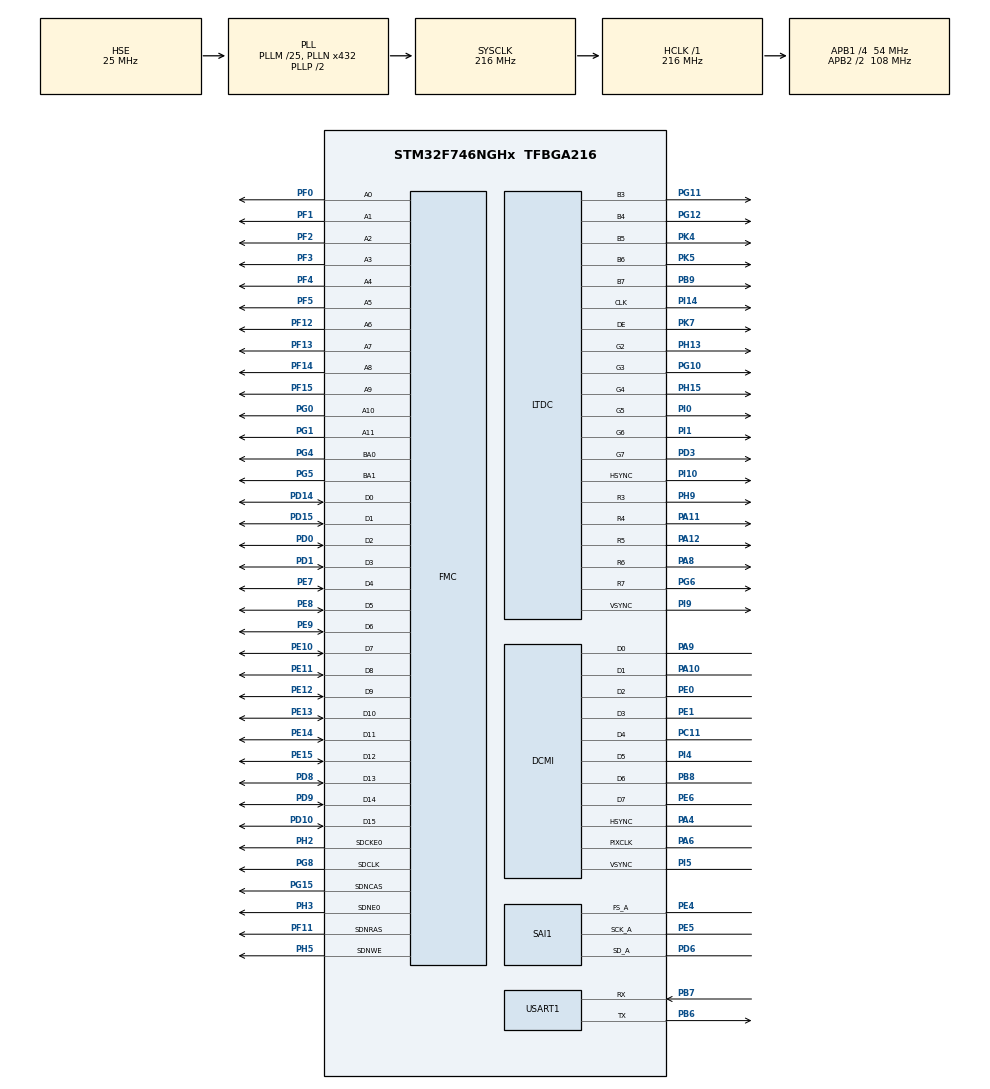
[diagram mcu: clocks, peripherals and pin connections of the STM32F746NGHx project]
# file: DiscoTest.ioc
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SH.FMC_D7_DA7.0=FMC_D7,sd-16b-d1
PK5.Signal=LTDC_B6
FMC.RCDDelay1=2
SH.FMC_A0.0=FMC_A0,12b-sda1
PG8.Signal=FMC_SDCLK
PG4.Signal=FMC_A14_BA0
PG0.Signal=FMC_A10
FMC.LoadToActiveDelay1=2
SH.FMC_D5_DA5.0=FMC_D5,sd-16b-d1
PG6.Mode=RGB565
SAI1.Instance-SAI_A_Master=SAI$Index_Block_A
RCC.SYSCLKSource=RCC_SYSCLKSOURCE_PLLCLK
SH.FMC_A15_BA1.0=FMC_BA1,FourSdramBanks1
SH.FMC_D9_DA9.0=FMC_D9,sd-16b-d1
PH5.Signal=FMC_SDNWE
PA4.Mode=Slave_8_bits_External_Synchro
SH.FMC_SDNWE.0=FMC_SDNWE,12b-sda1
PH9.Signal=LTDC_R3
SH.FMC_D11_DA11.0=FMC_D11,sd-16b-d1
RCC.APB2TimFreq_Value=216000000
PB6.Signal=USART1_TX
PH1/OSC_OUT.Signal=RCC_OSC_OUT
PB6.Mode=Asynchronous
PD0.Signal=FMC_D2_DA2
PD8.Signal=FMC_D13_DA13
PE5.Signal=SAI1_SCK_A
PE1.Signal=DCMI_D3
FMC.SelfRefreshTime1=4
LTDC.PixelFormat_L0=LTDC_PIXEL_FORMAT_RGB565
PK7.Mode=RGB565
PE9.Signal=FMC_D6_DA6
SH.FMC_A2.0=FMC_A2,12b-sda1
PA8.Signal=LTDC_R6
SH.FMC_D1_DA1.0=FMC_D1,sd-16b-d1
PF3.Signal=FMC_A3
PD3.Mode=RGB565
PE10.Signal=FMC_D7_DA7
LTDC.HSync=41
PB9.Signal=LTDC_B7
Mcu.Package=TFBGA216
NVIC.TimeBase=TIM1_UP_TIM10_IRQn
NVIC.TimeBaseIP=TIM1
PA10.Signal=DCMI_D1
FMC.WriteRecoveryTime1=2
PC11.Mode=Slave_8_bits_External_Synchro
SAI1.VirtualMode-SAI_A_Master=VM_MASTER
SH.FMC_A1.0=FMC_A1,12b-sda1
PH2.Signal=FMC_SDCKE0
RCC.APB2CLKDivider=RCC_HCLK_DIV2
SH.FMC_SDCLK.0=FMC_SDCLK,12b-sda1
LTDC.VSync=10
PF14.Signal=FMC_A8
RCC.APB1TimFreq_Value=108000000
VP_DMA2D_VS_DMA2D.Mode=DMA2D_Activate
FMC.RowCycleDelay2=6
FMC.RowCycleDelay1=6
SH.FMC_D3_DA3.0=FMC_D3,sd-16b-d1
PD15.Signal=FMC_D1_DA1
PG12.Signal=LTDC_B4
PK4.Signal=LTDC_B5
SH.FMC_A4.0=FMC_A4,12b-sda1
PH15.Signal=LTDC_G4
FREERTOS.Tasks01=defaultTask,24,1280,StartDefaultTask,Default,NULL,Dynamic,NULL,NULL;myTask02,8,128,StartTask02,Default,NULL,Dynamic,NULL,NULL;myTask03,8,128,StartTask03,Default,NULL,Dynamic,NULL,NULL;myTask04,8,128,StartTask04,Default,NULL,Dynamic,NULL,NULL;myTask05,8,128,StartTask05,Default,NULL,Dynamic,NULL,NULL
PH13.Signal=LTDC_G2
PI4.Mode=Slave_8_bits_External_Synchro
PG5.Signal=FMC_A15_BA1
SH.FMC_D10_DA10.0=FMC_D10,sd-16b-d1
PD3.Signal=LTDC_G7
PE1.Mode=Slave_8_bits_External_Synchro
PI10.Mode=RGB565
PD1.Signal=FMC_D3_DA3
RCC.APB1CLKDivider=RCC_HCLK_DIV4
PD6.Mode=SAI_A_Master
SAI1.RealAudioFreq-SAI_A_Master=187.5 KHz
PG10.Signal=LTDC_G3
PD10.Signal=FMC_D15_DA15
SH.FMC_A3.0=FMC_A3,12b-sda1
FMC.CASLatency1=FMC_SDRAM_CAS_LATENCY_2
SH.FMC_D15_DA15.0=FMC_D15,sd-16b-d1
PH9.Mode=RGB565
PA9.Signal=DCMI_D0
SH.FMC_A6.0=FMC_A6,12b-sda1
PE14.Signal=FMC_D11_DA11
PE6.Mode=Slave_8_bits_External_Synchro
PE15.Signal=FMC_D12_DA12
PE8.Signal=FMC_D5_DA5
PI1.Signal=LTDC_G6
PF13.Signal=FMC_A7
SH.FMC_SDNCAS.0=FMC_SDNCAS,12b-sda1
PA13.Mode=Serial_Wire
PA4.Signal=DCMI_HSYNC
PK4.Mode=RGB565
PG11.Mode=RGB565
SH.FMC_A5.0=FMC_A5,12b-sda1
PA11.Signal=LTDC_R4
ProjectManager.HeapSize=0x2000
NVIC.TIM1_UP_TIM10_IRQn=true\:0\:0\:false\:false\:true\:false\:false\:true
NVIC.PriorityGroup=NVIC_PRIORITYGROUP_4
PB8.Mode=Slave_8_bits_External_Synchro
PA8.Mode=RGB565
PF4.Signal=FMC_A4
Mcu.Family=STM32F7
PK7.Signal=LTDC_DE
PA6.Mode=Slave_8_bits_External_Synchro
SH.FMC_A8.0=FMC_A8,12b-sda1
RCC.CortexFreq_Value=216000000
PG6.Signal=LTDC_R7
SH.FMC_D14_DA14.0=FMC_D14,sd-16b-d1
LTDC.HBP=73
SH.FMC_D6_DA6.0=FMC_D6,sd-16b-d1
PA11.Mode=RGB565
SH.FMC_A14_BA0.0=FMC_BA0,FourSdramBanks1
SH.FMC_A11.0=FMC_A11,12b-sda1
PI5.Mode=Slave_8_bits_External_Synchro
PG11.Signal=LTDC_B3
PG15.Signal=FMC_SDNCAS
ProjectManager.StackSize=0x4000
VP_FREERTOS_VS_CMSIS_V2.Mode=CMSIS_V2
PH3.Mode=SdramChipSelect1_1
SH.FMC_A7.0=FMC_A7,12b-sda1
PA12.Signal=LTDC_R5
PH0/OSC_IN.Mode=HSE-External-Oscillator
RCC.HCLKFreq_Value=216000000
LTDC.WindowX1_L0=480
PF12.Signal=FMC_A6
PI9.Mode=RGB565
SH.FMC_A10.0=FMC_A10,12b-sda1
RCC.AHBFreq_Value=216000000
RCC.HSE_VALUE=25000000
SH.FMC_D8_DA8.0=FMC_D8,sd-16b-d1
FMC.ExitSelfRefreshDelay1=6
FMC.RPDelay2=2
FMC.RPDelay1=2
PI14.Mode=RGB565
SH.FMC_D2_DA2.0=FMC_D2,sd-16b-d1
PE13.Signal=FMC_D10_DA10
PA14.Mode=Serial_Wire
PI5.Signal=DCMI_VSYNC
VP_SYS_VS_tim1.Mode=TIM1
PI0.Signal=LTDC_G5
PF11.Signal=FMC_SDNRAS
LTDC.HFP=32
PB7.Signal=USART1_RX
PE4.Mode=SAI_A_Master
SH.FMC_SDNRAS.0=FMC_SDNRAS,12b-sda1
LTDC.ActiveW=480
PH1/OSC_OUT.Mode=HSE-External-Oscillator
PE4.Signal=SAI1_FS_A
PA6.Signal=DCMI_PIXCLK
SH.FMC_D0_DA0.0=FMC_D0,sd-16b-d1
SH.FMC_A9.0=FMC_A9,12b-sda1
SH.FMC_D4_DA4.0=FMC_D4,sd-16b-d1
PI1.Mode=RGB565
PF5.Signal=FMC_A5
PF0.Signal=FMC_A0
PH2.Mode=SdramChipSelect1_1
PE7.Signal=FMC_D4_DA4
PD6.Signal=SAI1_SD_A
RCC.PLLSourceVirtual=RCC_PLLSOURCE_HSE
CORTEX_M7.CPU_ICache=Enabled
LTDC.WindowY1_L0=272
PA10.Mode=Slave_8_bits_External_Synchro
PG1.Signal=FMC_A11
PC11.Signal=DCMI_D4
PI14.Signal=LTDC_CLK
PG10.Mode=RGB565
PI10.Signal=LTDC_HSYNC
PD9.Signal=FMC_D14_DA14
SAI1.MClockEnable-SAI_A_Master=SAI_MASTERCLOCK_DISABLE
USART1.VirtualMode-Asynchronous=VM_ASYNC
PA13.Signal=SYS_JTMS-SWDIO
PA9.Mode=Slave_8_bits_External_Synchro
ProjectManager.TargetToolchain=STM32CubeIDE
SH.FMC_D13_DA13.0=FMC_D13,sd-16b-d1
LTDC.ActiveH=272
SAI1.ErrorAudioFreq-SAI_A_Master=-2.34 %
PB9.Mode=RGB565
PI0.Mode=RGB565
PF2.Signal=FMC_A2
RCC.USBFreq_Value=216000000
PH13.Mode=RGB565
PE11.Signal=FMC_D8_DA8
RCC.LSE_VALUE=32768
PK5.Mode=RGB565
board=custom
PG12.Mode=RGB565
RCC.VCOOutputFreq_Value=432000000
PI9.Signal=LTDC_VSYNC
PH0/OSC_IN.Signal=RCC_OSC_IN
RCC.APB2Freq_Value=108000000
LTDC.Layers=0
PI4.Signal=DCMI_D5
PE5.Mode=SAI_A_Master
SH.FMC_D12_DA12.0=FMC_D12,sd-16b-d1
PF15.Signal=FMC_A9
PF1.Signal=FMC_A1
PE6.Signal=DCMI_D7
Mcu.Name=STM32F746NGHx
PE0.Signal=DCMI_D2
PE12.Signal=FMC_D9_DA9
PH15.Mode=RGB565
PD14.Signal=FMC_D0_DA0
LTDC.WindowY0_L0=0
RCC.SYSCLKFreq_VALUE=216000000
PA12.Mode=RGB565
LTDC.WindowX0_L0=0
PB7.Mode=Asynchronous
PA14.Signal=SYS_JTCK-SWCLK
RCC.HSI_VALUE=16000000
PH3.Signal=FMC_SDNE0
RCC.PLLM=25
RCC.PLLN=432
PB8.Signal=DCMI_D6
CORTEX_M7.CPU_DCache=Enabled
RCC.APB1Freq_Value=54000000
PE0.Mode=Slave_8_bits_External_Synchro

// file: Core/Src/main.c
/* USER CODE BEGIN Header */
/**
  ******************************************************************************
  * @file           : main.c
  * @brief          : Main program body
  ******************************************************************************
  * @attention
  *
  * <h2><center>&copy; Copyright (c) 2021 STMicroelectronics.
  * All rights reserved.</center></h2>
  *
  * This software component is licensed by ST under Ultimate Liberty license
  * SLA0044, the "License"; You may not use this file except in compliance with
  * the License. You may obtain a copy of the License at:
  *                             www.st.com/SLA0044
  *
  ******************************************************************************
  */
/* USER CODE END Header */
#include "main.h"
#include "cmsis_os.h"

/* USER CODE BEGIN Includes */

#include "stdlib.h"
#include "stm32746g_discovery.h"
#include "stm32746g_discovery_lcd.h"
#include "stm32746g_discovery_camera.h"

/* USER CODE END Includes */

DCMI_HandleTypeDef hdcmi;

DMA2D_HandleTypeDef hdma2d;

LTDC_HandleTypeDef hltdc;

SAI_HandleTypeDef hsai_BlockA1;

UART_HandleTypeDef huart1;

SDRAM_HandleTypeDef hsdram1;

/* Definitions for defaultTask */
osThreadId_t defaultTaskHandle;
const osThreadAttr_t defaultTask_attributes = {
  .name = "defaultTask",
  .stack_size = 1280 * 4,
  .priority = (osPriority_t) osPriorityNormal,
};
/* Definitions for myTask02 */
osThreadId_t myTask02Handle;
const osThreadAttr_t myTask02_attributes = {
  .name = "myTask02",
  .stack_size = 128 * 4,
  .priority = (osPriority_t) osPriorityLow,
};
/* Definitions for myTask03 */
osThreadId_t myTask03Handle;
const osThreadAttr_t myTask03_attributes = {
  .name = "myTask03",
  .stack_size = 128 * 4,
  .priority = (osPriority_t) osPriorityLow,
};
/* Definitions for myTask04 */
osThreadId_t myTask04Handle;
const osThreadAttr_t myTask04_attributes = {
  .name = "myTask04",
  .stack_size = 128 * 4,
  .priority = (osPriority_t) osPriorityLow,
};
/* Definitions for myTask05 */
osThreadId_t myTask05Handle;
const osThreadAttr_t myTask05_attributes = {
  .name = "myTask05",
  .stack_size = 128 * 4,
  .priority = (osPriority_t) osPriorityLow,
};
/* USER CODE BEGIN PV */

#ifndef USE_FULL_ASSERT
uint32_t    ErrorCounter = 0;
#endif

/* USER CODE END PV */

void SystemClock_Config(void);
static void MX_GPIO_Init(void);
static void MX_USART1_UART_Init(void);
static void MX_DMA2D_Init(void);
static void MX_FMC_Init(void);
static void MX_LTDC_Init(void);
static void MX_DCMI_Init(void);
static void MX_SAI1_Init(void);
void StartDefaultTask(void *argument);
void StartTask02(void *argument);
void StartTask03(void *argument);
void StartTask04(void *argument);
void StartTask05(void *argument);

/* USER CODE BEGIN 0 */
#define LCD_FRAME_BUFFER	SDRAM_DEVICE_ADDR
/* USER CODE END 0 */

int main(void)
{

  /* Enable I-Cache---------------------------------------------------------*/
  SCB_EnableICache();

  /* Enable D-Cache---------------------------------------------------------*/
  SCB_EnableDCache();

  /* MCU Configuration--------------------------------------------------------*/

  /* Reset of all peripherals, Initializes the Flash interface and the Systick. */
  HAL_Init();

  /* Configure the system clock */
  SystemClock_Config();

  /* Initialize all configured peripherals */
  MX_GPIO_Init();
  MX_USART1_UART_Init();
  MX_DMA2D_Init();
  MX_FMC_Init();
  MX_LTDC_Init();
  MX_DCMI_Init();
  MX_SAI1_Init();
  /* USER CODE BEGIN 2 */

  BSP_LCD_Init();
  BSP_LCD_LayerDefaultInit(LTDC_ACTIVE_LAYER, LCD_FRAME_BUFFER);
  BSP_LCD_SelectLayer(LTDC_ACTIVE_LAYER);
  BSP_LCD_DisplayOn();
  BSP_LCD_Clear(LCD_COLOR_BLACK);

  BSP_CAMERA_Init();
  /* USER CODE END 2 */

  /* Init scheduler */
  osKernelInitialize();

  /* Create the thread(s) */
  /* creation of defaultTask */
  defaultTaskHandle = osThreadNew(StartDefaultTask, NULL, &defaultTask_attributes);

  /* creation of myTask02 */
  myTask02Handle = osThreadNew(StartTask02, NULL, &myTask02_attributes);

  /* creation of myTask03 */
  myTask03Handle = osThreadNew(StartTask03, NULL, &myTask03_attributes);

  /* creation of myTask04 */
  myTask04Handle = osThreadNew(StartTask04, NULL, &myTask04_attributes);

  /* creation of myTask05 */
  myTask05Handle = osThreadNew(StartTask05, NULL, &myTask05_attributes);

  /* Start scheduler */
  osKernelStart();

  /* We should never get here as control is now taken by the scheduler */
  /* Infinite loop */
  while (1)
  {

  }
}

void SystemClock_Config(void)
{
  RCC_OscInitTypeDef RCC_OscInitStruct = {0};
  RCC_ClkInitTypeDef RCC_ClkInitStruct = {0};
  RCC_PeriphCLKInitTypeDef PeriphClkInitStruct = {0};

  /** Configure the main internal regulator output voltage
  */
  __HAL_RCC_PWR_CLK_ENABLE();
  __HAL_PWR_VOLTAGESCALING_CONFIG(PWR_REGULATOR_VOLTAGE_SCALE1);
  /** Initializes the RCC Oscillators according to the specified parameters
  * in the RCC_OscInitTypeDef structure.
  */
  RCC_OscInitStruct.OscillatorType = RCC_OSCILLATORTYPE_HSE;
  RCC_OscInitStruct.HSEState = RCC_HSE_ON;
  RCC_OscInitStruct.PLL.PLLState = RCC_PLL_ON;
  RCC_OscInitStruct.PLL.PLLSource = RCC_PLLSOURCE_HSE;
  RCC_OscInitStruct.PLL.PLLM = 25;
  RCC_OscInitStruct.PLL.PLLN = 432;
  RCC_OscInitStruct.PLL.PLLP = RCC_PLLP_DIV2;
  RCC_OscInitStruct.PLL.PLLQ = 2;
  if (HAL_RCC_OscConfig(&RCC_OscInitStruct) != HAL_OK)
  {
    Error_Handler();
  }
  /** Activate the Over-Drive mode
  */
  if (HAL_PWREx_EnableOverDrive() != HAL_OK)
  {
    Error_Handler();
  }
  /** Initializes the CPU, AHB and APB buses clocks
  */
  RCC_ClkInitStruct.ClockType = RCC_CLOCKTYPE_HCLK|RCC_CLOCKTYPE_SYSCLK
                              |RCC_CLOCKTYPE_PCLK1|RCC_CLOCKTYPE_PCLK2;
  RCC_ClkInitStruct.SYSCLKSource = RCC_SYSCLKSOURCE_PLLCLK;
  RCC_ClkInitStruct.AHBCLKDivider = RCC_SYSCLK_DIV1;
  RCC_ClkInitStruct.APB1CLKDivider = RCC_HCLK_DIV4;
  RCC_ClkInitStruct.APB2CLKDivider = RCC_HCLK_DIV2;

  if (HAL_RCC_ClockConfig(&RCC_ClkInitStruct, FLASH_LATENCY_7) != HAL_OK)
  {
    Error_Handler();
  }
  PeriphClkInitStruct.PeriphClockSelection = RCC_PERIPHCLK_LTDC|RCC_PERIPHCLK_USART1
                              |RCC_PERIPHCLK_SAI1;
  PeriphClkInitStruct.PLLSAI.PLLSAIN = 192;
  PeriphClkInitStruct.PLLSAI.PLLSAIR = 2;
  PeriphClkInitStruct.PLLSAI.PLLSAIQ = 2;
  PeriphClkInitStruct.PLLSAI.PLLSAIP = RCC_PLLSAIP_DIV2;
  PeriphClkInitStruct.PLLSAIDivQ = 1;
  PeriphClkInitStruct.PLLSAIDivR = RCC_PLLSAIDIVR_2;
  PeriphClkInitStruct.Sai1ClockSelection = RCC_SAI1CLKSOURCE_PLLSAI;
  PeriphClkInitStruct.Usart1ClockSelection = RCC_USART1CLKSOURCE_PCLK2;
  if (HAL_RCCEx_PeriphCLKConfig(&PeriphClkInitStruct) != HAL_OK)
  {
    Error_Handler();
  }
}

static void MX_DCMI_Init(void)
{

  hdcmi.Instance = DCMI;
  hdcmi.Init.SynchroMode = DCMI_SYNCHRO_HARDWARE;
  hdcmi.Init.PCKPolarity = DCMI_PCKPOLARITY_FALLING;
  hdcmi.Init.VSPolarity = DCMI_VSPOLARITY_LOW;
  hdcmi.Init.HSPolarity = DCMI_HSPOLARITY_LOW;
  hdcmi.Init.CaptureRate = DCMI_CR_ALL_FRAME;
  hdcmi.Init.ExtendedDataMode = DCMI_EXTEND_DATA_8B;
  hdcmi.Init.JPEGMode = DCMI_JPEG_DISABLE;
  hdcmi.Init.ByteSelectMode = DCMI_BSM_ALL;
  hdcmi.Init.ByteSelectStart = DCMI_OEBS_ODD;
  hdcmi.Init.LineSelectMode = DCMI_LSM_ALL;
  hdcmi.Init.LineSelectStart = DCMI_OELS_ODD;
  if (HAL_DCMI_Init(&hdcmi) != HAL_OK)
  {
    Error_Handler();
  }

}

static void MX_DMA2D_Init(void)
{

  hdma2d.Instance = DMA2D;
  hdma2d.Init.Mode = DMA2D_M2M;
  hdma2d.Init.ColorMode = DMA2D_OUTPUT_ARGB8888;
  hdma2d.Init.OutputOffset = 0;
  hdma2d.LayerCfg[1].InputOffset = 0;
  hdma2d.LayerCfg[1].InputColorMode = DMA2D_INPUT_ARGB8888;
  hdma2d.LayerCfg[1].AlphaMode = DMA2D_NO_MODIF_ALPHA;
  hdma2d.LayerCfg[1].InputAlpha = 0;
  if (HAL_DMA2D_Init(&hdma2d) != HAL_OK)
  {
    Error_Handler();
  }
  if (HAL_DMA2D_ConfigLayer(&hdma2d, 1) != HAL_OK)
  {
    Error_Handler();
  }

}

static void MX_LTDC_Init(void)
{

  LTDC_LayerCfgTypeDef pLayerCfg = {0};

  hltdc.Instance = LTDC;
  hltdc.Init.HSPolarity = LTDC_HSPOLARITY_AL;
  hltdc.Init.VSPolarity = LTDC_VSPOLARITY_AL;
  hltdc.Init.DEPolarity = LTDC_DEPOLARITY_AL;
  hltdc.Init.PCPolarity = LTDC_PCPOLARITY_IPC;
  hltdc.Init.HorizontalSync = 40;
  hltdc.Init.VerticalSync = 9;
  hltdc.Init.AccumulatedHBP = 113;
  hltdc.Init.AccumulatedVBP = 11;
  hltdc.Init.AccumulatedActiveW = 593;
  hltdc.Init.AccumulatedActiveH = 283;
  hltdc.Init.TotalWidth = 625;
  hltdc.Init.TotalHeigh = 285;
  hltdc.Init.Backcolor.Blue = 0;
  hltdc.Init.Backcolor.Green = 0;
  hltdc.Init.Backcolor.Red = 0;
  if (HAL_LTDC_Init(&hltdc) != HAL_OK)
  {
    Error_Handler();
  }
  pLayerCfg.WindowX0 = 0;
  pLayerCfg.WindowX1 = 480;
  pLayerCfg.WindowY0 = 0;
  pLayerCfg.WindowY1 = 272;
  pLayerCfg.PixelFormat = LTDC_PIXEL_FORMAT_RGB565;
  pLayerCfg.Alpha = 0;
  pLayerCfg.Alpha0 = 0;
  pLayerCfg.BlendingFactor1 = LTDC_BLENDING_FACTOR1_CA;
  pLayerCfg.BlendingFactor2 = LTDC_BLENDING_FACTOR2_CA;
  pLayerCfg.FBStartAdress = 0;
  pLayerCfg.ImageWidth = 0;
  pLayerCfg.ImageHeight = 0;
  pLayerCfg.Backcolor.Blue = 0;
  pLayerCfg.Backcolor.Green = 0;
  pLayerCfg.Backcolor.Red = 0;
  if (HAL_LTDC_ConfigLayer(&hltdc, &pLayerCfg, 0) != HAL_OK)
  {
    Error_Handler();
  }

}

static void MX_SAI1_Init(void)
{

  hsai_BlockA1.Instance = SAI1_Block_A;
  hsai_BlockA1.Init.Protocol = SAI_FREE_PROTOCOL;
  hsai_BlockA1.Init.AudioMode = SAI_MODEMASTER_TX;
  hsai_BlockA1.Init.DataSize = SAI_DATASIZE_8;
  hsai_BlockA1.Init.FirstBit = SAI_FIRSTBIT_MSB;
  hsai_BlockA1.Init.ClockStrobing = SAI_CLOCKSTROBING_FALLINGEDGE;
  hsai_BlockA1.Init.Synchro = SAI_ASYNCHRONOUS;
  hsai_BlockA1.Init.OutputDrive = SAI_OUTPUTDRIVE_DISABLE;
  hsai_BlockA1.Init.NoDivider = SAI_MASTERDIVIDER_ENABLE;
  hsai_BlockA1.Init.FIFOThreshold = SAI_FIFOTHRESHOLD_EMPTY;
  hsai_BlockA1.Init.AudioFrequency = SAI_AUDIO_FREQUENCY_192K;
  hsai_BlockA1.Init.SynchroExt = SAI_SYNCEXT_DISABLE;
  hsai_BlockA1.Init.MonoStereoMode = SAI_STEREOMODE;
  hsai_BlockA1.Init.CompandingMode = SAI_NOCOMPANDING;
  hsai_BlockA1.Init.TriState = SAI_OUTPUT_NOTRELEASED;
  hsai_BlockA1.FrameInit.FrameLength = 8;
  hsai_BlockA1.FrameInit.ActiveFrameLength = 1;
  hsai_BlockA1.FrameInit.FSDefinition = SAI_FS_STARTFRAME;
  hsai_BlockA1.FrameInit.FSPolarity = SAI_FS_ACTIVE_LOW;
  hsai_BlockA1.FrameInit.FSOffset = SAI_FS_FIRSTBIT;
  hsai_BlockA1.SlotInit.FirstBitOffset = 0;
  hsai_BlockA1.SlotInit.SlotSize = SAI_SLOTSIZE_DATASIZE;
  hsai_BlockA1.SlotInit.SlotNumber = 1;
  hsai_BlockA1.SlotInit.SlotActive = 0x00000000;
  if (HAL_SAI_Init(&hsai_BlockA1) != HAL_OK)
  {
    Error_Handler();
  }

}

static void MX_USART1_UART_Init(void)
{

  huart1.Instance = USART1;
  huart1.Init.BaudRate = 115200;
  huart1.Init.WordLength = UART_WORDLENGTH_8B;
  huart1.Init.StopBits = UART_STOPBITS_1;
  huart1.Init.Parity = UART_PARITY_NONE;
  huart1.Init.Mode = UART_MODE_TX_RX;
  huart1.Init.HwFlowCtl = UART_HWCONTROL_NONE;
  huart1.Init.OverSampling = UART_OVERSAMPLING_16;
  huart1.Init.OneBitSampling = UART_ONE_BIT_SAMPLE_DISABLE;
  huart1.AdvancedInit.AdvFeatureInit = UART_ADVFEATURE_NO_INIT;
  if (HAL_UART_Init(&huart1) != HAL_OK)
  {
    Error_Handler();
  }

}

/* FMC initialization function */
static void MX_FMC_Init(void)
{

  FMC_SDRAM_TimingTypeDef SdramTiming = {0};

  /** Perform the SDRAM1 memory initialization sequence
  */
  hsdram1.Instance = FMC_SDRAM_DEVICE;
  /* hsdram1.Init */
  hsdram1.Init.SDBank = FMC_SDRAM_BANK1;
  hsdram1.Init.ColumnBitsNumber = FMC_SDRAM_COLUMN_BITS_NUM_8;
  hsdram1.Init.RowBitsNumber = FMC_SDRAM_ROW_BITS_NUM_12;
  hsdram1.Init.MemoryDataWidth = FMC_SDRAM_MEM_BUS_WIDTH_16;
  hsdram1.Init.InternalBankNumber = FMC_SDRAM_INTERN_BANKS_NUM_4;
  hsdram1.Init.CASLatency = FMC_SDRAM_CAS_LATENCY_2;
  hsdram1.Init.WriteProtection = FMC_SDRAM_WRITE_PROTECTION_DISABLE;
  hsdram1.Init.SDClockPeriod = FMC_SDRAM_CLOCK_DISABLE;
  hsdram1.Init.ReadBurst = FMC_SDRAM_RBURST_DISABLE;
  hsdram1.Init.ReadPipeDelay = FMC_SDRAM_RPIPE_DELAY_0;
  /* SdramTiming */
  SdramTiming.LoadToActiveDelay = 2;
  SdramTiming.ExitSelfRefreshDelay = 6;
  SdramTiming.SelfRefreshTime = 4;
  SdramTiming.RowCycleDelay = 6;
  SdramTiming.WriteRecoveryTime = 2;
  SdramTiming.RPDelay = 2;
  SdramTiming.RCDDelay = 2;

  if (HAL_SDRAM_Init(&hsdram1, &SdramTiming) != HAL_OK)
  {
    Error_Handler( );
  }

}

static void MX_GPIO_Init(void)
{

  /* GPIO Ports Clock Enable */
  __HAL_RCC_GPIOE_CLK_ENABLE();
  __HAL_RCC_GPIOB_CLK_ENABLE();
  __HAL_RCC_GPIOA_CLK_ENABLE();
  __HAL_RCC_GPIOG_CLK_ENABLE();
  __HAL_RCC_GPIOD_CLK_ENABLE();
  __HAL_RCC_GPIOC_CLK_ENABLE();
  __HAL_RCC_GPIOI_CLK_ENABLE();
  __HAL_RCC_GPIOK_CLK_ENABLE();
  __HAL_RCC_GPIOF_CLK_ENABLE();
  __HAL_RCC_GPIOH_CLK_ENABLE();

}

void StartDefaultTask(void *argument)
{
  /* USER CODE BEGIN 5 */
  /* Infinite loop */
  for(;;)
  {
	BSP_LCD_SetTextColor(LCD_COLOR_DARKBLUE);
	BSP_LCD_FillRect(0, 136, 96, 136);
    osDelay(200);
  }
  /* USER CODE END 5 */
}

void StartTask02(void *argument)
{
  for(;;)
  {
    osDelay(1);
  }
}

void StartTask03(void *argument)
{
  for(;;)
  {
    osDelay(1);
  }
}

void StartTask04(void *argument)
{
  for(;;)
  {
    osDelay(1);
  }
}

void StartTask05(void *argument)
{
  for(;;)
  {
    osDelay(1);
  }
}

 /**
  * @brief  Period elapsed callback in non blocking mode
  * @note   This function is called  when TIM1 interrupt took place, inside
  * HAL_TIM_IRQHandler(). It makes a direct call to HAL_IncTick() to increment
  * a global variable "uwTick" used as application time base.
  * @param  htim : TIM handle
  * @retval None
  */
void HAL_TIM_PeriodElapsedCallback(TIM_HandleTypeDef *htim)
{
  if (htim->Instance == TIM1) {
    HAL_IncTick();
  }
}

void Error_Handler(void)
{
  __disable_irq();
  while (1)
  {
  }
}

/************************ (C) COPYRIGHT STMicroelectronics *****END OF FILE****/
